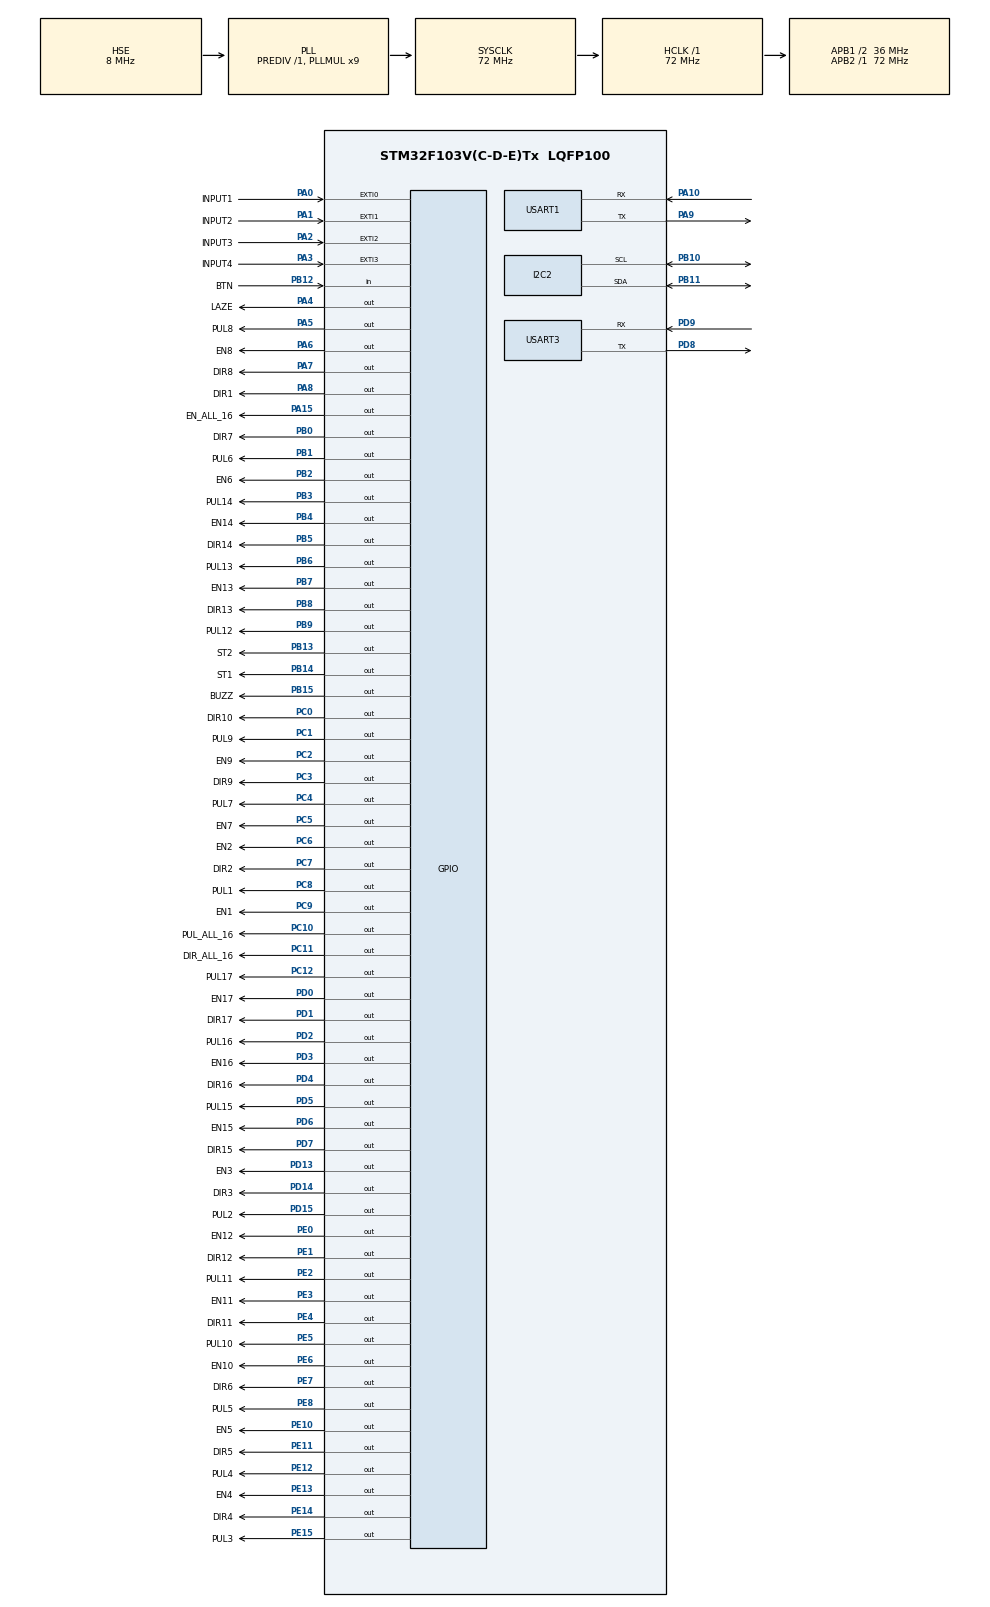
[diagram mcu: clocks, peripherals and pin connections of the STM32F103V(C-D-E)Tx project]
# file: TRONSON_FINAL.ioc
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I2C2.I2C_Mode=I2C_Standard
Mcu.Family=STM32F1
Mcu.Name=STM32F103V(C-D-E)Tx
Mcu.Package=LQFP100
NVIC.EXTI0_IRQn=true\:15\:0\:true\:false\:true\:true\:true\:true
NVIC.EXTI1_IRQn=true\:15\:0\:true\:false\:true\:true\:true\:true
NVIC.EXTI2_IRQn=true\:15\:0\:true\:false\:true\:true\:true\:true
NVIC.EXTI3_IRQn=true\:15\:0\:true\:false\:true\:true\:true\:true
NVIC.PriorityGroup=NVIC_PRIORITYGROUP_4
NVIC.TIM2_IRQn=true\:0\:0\:false\:false\:true\:true\:true\:true
NVIC.TIM3_IRQn=true\:2\:0\:true\:false\:true\:true\:true\:true
NVIC.TIM4_IRQn=true\:0\:0\:false\:false\:true\:true\:true\:true
NVIC.TIM5_IRQn=true\:0\:0\:false\:false\:true\:true\:true\:true
NVIC.TIM6_IRQn=true\:0\:0\:false\:false\:true\:true\:true\:true
NVIC.USART1_IRQn=true\:0\:0\:false\:false\:true\:true\:true\:true
NVIC.USART3_IRQn=true\:0\:0\:false\:false\:true\:true\:true\:true
OSC_IN.Mode=HSE-External-Oscillator
OSC_IN.Signal=RCC_OSC_IN
OSC_OUT.Mode=HSE-External-Oscillator
OSC_OUT.Signal=RCC_OSC_OUT
PA0-WKUP.GPIO_Label=INPUT1
PA0-WKUP.GPIO_ModeDefaultEXTI=GPIO_MODE_IT_RISING_FALLING
PA0-WKUP.GPIO_PuPd=GPIO_PULLUP
PA0-WKUP.Signal=GPXTI0
PA1.GPIO_Label=INPUT2
PA1.GPIO_ModeDefaultEXTI=GPIO_MODE_IT_RISING_FALLING
PA1.GPIO_PuPd=GPIO_PULLUP
PA1.Signal=GPXTI1
PA10.Mode=Asynchronous
PA10.Signal=USART1_RX
PA13.Signal=SYS_JTMS-SWDIO
PA14.Signal=SYS_JTCK-SWCLK
PA15.GPIO_Label=EN_ALL_16
PA15.GPIO_ModeDefaultOutputPP=GPIO_MODE_OUTPUT_PP
PA15.GPIO_PuPd=GPIO_NOPULL
PA15.GPIO_Speed=GPIO_SPEED_FREQ_LOW
PA15.PinState=GPIO_PIN_RESET
PA15.Signal=GPIO_Output
PA2.GPIO_Label=INPUT3
PA2.GPIO_ModeDefaultEXTI=GPIO_MODE_IT_RISING_FALLING
PA2.GPIO_PuPd=GPIO_PULLUP
PA2.Signal=GPXTI2
PA3.GPIO_Label=INPUT4
PA3.GPIO_ModeDefaultEXTI=GPIO_MODE_IT_RISING_FALLING
PA3.GPIO_PuPd=GPIO_PULLUP
PA3.Signal=GPXTI3
PA4.GPIO_Label=LAZE
PA4.Signal=GPIO_Output
PA5.GPIO_Label=PUL8
PA5.Signal=GPIO_Output
PA6.GPIO_Label=EN8
PA6.Signal=GPIO_Output
PA7.GPIO_Label=DIR8
PA7.Signal=GPIO_Output
PA8.GPIO_Label=DIR1
PA8.Signal=GPIO_Output
PA9.Mode=Asynchronous
PA9.Signal=USART1_TX
PB0.GPIO_Label=DIR7
PB0.Signal=GPIO_Output
PB1.GPIO_Label=PUL6
PB1.Signal=GPIO_Output
PB10.Mode=I2C
PB10.Signal=I2C2_SCL
PB11.Mode=I2C
PB11.Signal=I2C2_SDA
PB12.GPIO_Label=BTN
PB12.Signal=GPIO_Input
PB13.GPIO_Label=ST2
PB13.Signal=GPIO_Output
PB14.GPIO_Label=ST1
PB14.Signal=GPIO_Output
PB15.GPIO_Label=BUZZ
PB15.Signal=GPIO_Output
PB2.GPIO_Label=EN6
PB2.Signal=GPIO_Output
PB3.GPIO_Label=PUL14
PB3.Signal=GPIO_Output
PB4.GPIO_Label=EN14
PB4.Signal=GPIO_Output
PB5.GPIO_Label=DIR14
PB5.Signal=GPIO_Output
PB6.GPIO_Label=PUL13
PB6.Signal=GPIO_Output
PB7.GPIO_Label=EN13
PB7.Signal=GPIO_Output
PB8.GPIO_Label=DIR13
PB8.Signal=GPIO_Output
PB9.GPIO_Label=PUL12
PB9.Signal=GPIO_Output
PC0.GPIO_Label=DIR10
PC0.Signal=GPIO_Output
PC1.GPIO_Label=PUL9
PC1.Signal=GPIO_Output
PC10.GPIO_Label=PUL_ALL_16
PC10.Signal=GPIO_Output
PC11.GPIO_Label=DIR_ALL_16
PC11.Signal=GPIO_Output
PC12.GPIO_Label=PUL17
PC12.Signal=GPIO_Output
PC14-OSC32_IN.Mode=LSE-External-Oscillator
PC14-OSC32_IN.Signal=RCC_OSC32_IN
PC15-OSC32_OUT.Mode=LSE-External-Oscillator
PC15-OSC32_OUT.Signal=RCC_OSC32_OUT
PC2.GPIO_Label=EN9
PC2.Signal=GPIO_Output
PC3.GPIO_Label=DIR9
PC3.Signal=GPIO_Output
PC4.GPIO_Label=PUL7
PC4.Signal=GPIO_Output
PC5.GPIO_Label=EN7
PC5.Signal=GPIO_Output
PC6.GPIO_Label=EN2
PC6.Signal=GPIO_Output
PC7.GPIO_Label=DIR2
PC7.Signal=GPIO_Output
PC8.GPIO_Label=PUL1
PC8.Signal=GPIO_Output
PC9.GPIO_Label=EN1
PC9.Signal=GPIO_Output
PD0.GPIO_Label=EN17
PD0.Signal=GPIO_Output
PD1.GPIO_Label=DIR17
PD1.Signal=GPIO_Output
PD12.Signal=S_TIM4_CH1
PD13.GPIO_Label=EN3
PD13.Signal=GPIO_Output
PD14.GPIO_Label=DIR3
PD14.Signal=GPIO_Output
PD15.GPIO_Label=PUL2
PD15.Signal=GPIO_Output
PD2.GPIO_Label=PUL16
PD2.Signal=GPIO_Output
PD3.GPIO_Label=EN16
PD3.Signal=GPIO_Output
PD4.GPIO_Label=DIR16
PD4.Signal=GPIO_Output
PD5.GPIO_Label=PUL15
PD5.Signal=GPIO_Output
PD6.GPIO_Label=EN15
PD6.Signal=GPIO_Output
PD7.GPIO_Label=DIR15
PD7.Signal=GPIO_Output
PD8.Mode=Asynchronous
PD8.Signal=USART3_TX
PD9.Mode=Asynchronous
PD9.Signal=USART3_RX
PE0.GPIO_Label=EN12
PE0.GPIO_PuPd=GPIO_PULLUP
PE0.Signal=GPIO_Output
PE1.GPIO_Label=DIR12
PE1.GPIO_PuPd=GPIO_PULLUP
PE1.Signal=GPIO_Output
PE10.GPIO_Label=EN5
PE10.Signal=GPIO_Output
PE11.GPIO_Label=DIR5
PE11.Signal=GPIO_Output
PE12.GPIO_Label=PUL4
PE12.Signal=GPIO_Output
PE13.GPIO_Label=EN4
PE13.Signal=GPIO_Output
PE14.GPIO_Label=DIR4
PE14.Signal=GPIO_Output
PE15.GPIO_Label=PUL3
PE15.Signal=GPIO_Output
PE2.GPIO_Label=PUL11
PE2.GPIO_PuPd=GPIO_PULLUP
PE2.Signal=GPIO_Output
PE3.GPIO_Label=EN11
PE3.GPIO_PuPd=GPIO_PULLUP
PE3.Signal=GPIO_Output
PE4.GPIO_Label=DIR11
PE4.GPIO_PuPd=GPIO_PULLUP
PE4.Signal=GPIO_Output
PE5.GPIO_Label=PUL10
PE5.GPIO_PuPd=GPIO_PULLUP
PE5.Signal=GPIO_Output
PE6.GPIO_Label=EN10
PE6.GPIO_PuPd=GPIO_PULLUP
PE6.Signal=GPIO_Output
PE7.GPIO_Label=DIR6
PE7.Signal=GPIO_Output
PE8.GPIO_Label=PUL5
PE8.Signal=GPIO_Output
PE9.Signal=S_TIM1_CH1
ProjectManager.HeapSize=0x200
ProjectManager.StackSize=0x400
ProjectManager.TargetToolchain=STM32CubeIDE
RCC.AHBFreq_Value=72000000
RCC.APB1CLKDivider=RCC_HCLK_DIV2
RCC.APB1Freq_Value=36000000
RCC.APB1TimFreq_Value=72000000
RCC.APB2Freq_Value=72000000
RCC.APB2TimFreq_Value=72000000
RCC.HCLKFreq_Value=72000000
RCC.PLLMUL=RCC_PLL_MUL9
RCC.PLLSourceVirtual=RCC_PLLSOURCE_HSE
RCC.RTCClockSelection=RCC_RTCCLKSOURCE_LSE
RCC.SYSCLKFreq_VALUE=72000000
RCC.SYSCLKSource=RCC_SYSCLKSOURCE_PLLCLK
RCC.USBFreq_Value=48000000
RCC.USBPrescaler=RCC_USBCLKSOURCE_PLL_DIV1_5
SH.S_TIM1_CH1.0=TIM1_CH1
SH.S_TIM4_CH1.0=TIM4_CH1
TIM2.Period=9999
TIM2.Prescaler=7199
TIM3.AutoReloadPreload=TIM_AUTORELOAD_PRELOAD_ENABLE
TIM3.Period=9
TIM3.Prescaler=71
TIM4.AutoReloadPreload=TIM_AUTORELOAD_PRELOAD_ENABLE
TIM4.Period=72*100-1
TIM4.Prescaler=1
TIM5.Period=72*400-1
TIM6.AutoReloadPreload=TIM_AUTORELOAD_PRELOAD_ENABLE
TIM6.Period=9999
TIM6.Prescaler=71
USART1.VirtualMode=VM_ASYNC
USART3.VirtualMode=VM_ASYNC
VP_RTC_VS_RTC_Activate.Mode=RTC_Enabled
VP_TIM2_VS_ClockSourceINT.Mode=Internal
VP_TIM3_VS_ClockSourceINT.Mode=Internal
VP_TIM4_VS_ClockSourceINT.Mode=Internal
VP_TIM5_VS_ClockSourceINT.Mode=Internal
VP_TIM6_VS_ClockSourceINT.Mode=Enable_Timer
board=custom

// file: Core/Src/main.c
/* USER CODE BEGIN Header */
/**
  ******************************************************************************
  * @file           : main.c
  * @brief          : Main program body
  ******************************************************************************
  * @attention
  *
  * Copyright (c) 2023 STMicroelectronics.
  * All rights reserved.
  *
  * This software is licensed under terms that can be found in the LICENSE file
  * in the root directory of this software component.
  * If no LICENSE file comes with this software, it is provided AS-IS.
  *
  * edit: 0703 2024
  * fix loi dung dong thoi 2 dong co.
  *
  ******************************************************************************
  */
/* USER CODE END Header */
#include "main.h"
#include "i2c.h"
#include "rtc.h"
#include "tim.h"
#include "usart.h"
#include "gpio.h"

/* USER CODE BEGIN Includes */
/* USER CODE BEGIN Includes */
//#include "usbd_cdc_if.h"
#include <stdio.h>
//#include "SEGGER_RTT.h"

#include "board_peripheral.h"
#include "appPcHandle.h"
#include "eeprom_24c32.h"
#include "myEepromUtility.h"
#include "driver_rtc.h"
/* USER CODE END Includes */

/* USER CODE BEGIN PM */
#ifdef __GNUC__
#define PUTCHAR_PROTOTYPE int __io_putchar(int ch)
#else
#define PUTCHAR_PROTOTYPE int fputc(int ch, FILE *f)
#endif

PUTCHAR_PROTOTYPE
{
	HAL_UART_Transmit(&huart3, (uint8_t *)&ch, 1, HAL_MAX_DELAY);
    return ch;
}
/* USER CODE END PM */

/* USER CODE BEGIN PV */
void HAL_UART_RxCpltCallback(UART_HandleTypeDef *huart)
{
    //app PC //
    if(huart->Instance==huart1.Instance)
    {
    	uartAppHandle(&myApp);
    }
    HAL_UART_Receive_IT(&huart1, &myApp.charRec,1); //app PC
}
/* USER CODE END PV */

void SystemClock_Config(void);
/* USER CODE BEGIN PFP */
void RemapPin_Init(void) {

	// remap PA15 to free is GPIO //
	RCC->APB2ENR |= RCC_APB2ENR_AFIOEN | RCC_APB2ENR_IOPAEN;
	AFIO->MAPR   |= AFIO_MAPR_SWJ_CFG_1;    // To Free PA15

	// disable jtag //
	__HAL_RCC_AFIO_CLK_ENABLE();
	__HAL_AFIO_REMAP_SWJ_NOJTAG();
}

/* USER CODE END PFP */

/* USER CODE BEGIN 0 */

static volatile uint32_t Tick = 0;
/* USER CODE END 0 */

int main(void)
{
  /* USER CODE BEGIN 1 */
  /* SCB->VTOR = (uint32_t)(0x08008000);
    __enable_irq();*/
  /* USER CODE END 1 */

  /* MCU Configuration--------------------------------------------------------*/

  /* Reset of all peripherals, Initializes the Flash interface and the Systick. */
  HAL_Init();

  /* Configure the system clock */
  SystemClock_Config();

  /* USER CODE BEGIN SysInit */
  RemapPin_Init();
  //SEGGER_RTT_ConfigUpBuffer(0, NULL, NULL, 0 , SEGGER_RTT_MODE_NO_BLOCK_SKIP);
  /* USER CODE END SysInit */

  /* Initialize all configured peripherals */
  MX_GPIO_Init();
  MX_I2C2_Init();
  MX_TIM4_Init();
  MX_USART3_UART_Init();
  MX_TIM2_Init();
  MX_TIM3_Init();
  MX_TIM5_Init();
  MX_TIM6_Init();
  MX_RTC_Init();
  MX_USART1_UART_Init();
  /* USER CODE BEGIN 2 */

  HAL_UART_Receive_IT(&huart1, &myApp.charRec, 1);          //app PC
  DISABLE_TIMER_ALARM;

  /* USER CODE END 2 */

  /* Infinite loop */
  /* USER CODE BEGIN WHILE */

	printf("-----------------------------------------------------\r\n");
	printf("1.Start Application 07/05/2024 by xuantn93@gmail.com \r\n");
	printf("2.CPU_FREQ = %d Hz \r\n",  HAL_RCC_GetSysClockFreq());
	printf("3.Update Release 20/03/2025 \r\n");

	HAL_GPIO_WritePin(DIR17_GPIO_Port, DIR17_Pin, 1);
	speaker_efect();
	pump_init();
	loadConfigInEeprom();

	while (1)
	{
      handleAppRequets();
    /* USER CODE END WHILE */

	}
}

void SystemClock_Config(void)
{
  RCC_OscInitTypeDef RCC_OscInitStruct = {0};
  RCC_ClkInitTypeDef RCC_ClkInitStruct = {0};
  RCC_PeriphCLKInitTypeDef PeriphClkInit = {0};

  /** Initializes the RCC Oscillators according to the specified parameters
  * in the RCC_OscInitTypeDef structure.
  */
  RCC_OscInitStruct.OscillatorType = RCC_OSCILLATORTYPE_HSE|RCC_OSCILLATORTYPE_LSE;
  RCC_OscInitStruct.HSEState = RCC_HSE_ON;
  RCC_OscInitStruct.HSEPredivValue = RCC_HSE_PREDIV_DIV1;
  RCC_OscInitStruct.LSEState = RCC_LSE_ON;
  RCC_OscInitStruct.HSIState = RCC_HSI_ON;
  RCC_OscInitStruct.PLL.PLLState = RCC_PLL_ON;
  RCC_OscInitStruct.PLL.PLLSource = RCC_PLLSOURCE_HSE;
  RCC_OscInitStruct.PLL.PLLMUL = RCC_PLL_MUL9;
  if (HAL_RCC_OscConfig(&RCC_OscInitStruct) != HAL_OK)
  {
    Error_Handler();
  }

  /** Initializes the CPU, AHB and APB buses clocks
  */
  RCC_ClkInitStruct.ClockType = RCC_CLOCKTYPE_HCLK|RCC_CLOCKTYPE_SYSCLK
                              |RCC_CLOCKTYPE_PCLK1|RCC_CLOCKTYPE_PCLK2;
  RCC_ClkInitStruct.SYSCLKSource = RCC_SYSCLKSOURCE_PLLCLK;
  RCC_ClkInitStruct.AHBCLKDivider = RCC_SYSCLK_DIV1;
  RCC_ClkInitStruct.APB1CLKDivider = RCC_HCLK_DIV2;
  RCC_ClkInitStruct.APB2CLKDivider = RCC_HCLK_DIV1;

  if (HAL_RCC_ClockConfig(&RCC_ClkInitStruct, FLASH_LATENCY_2) != HAL_OK)
  {
    Error_Handler();
  }
  PeriphClkInit.PeriphClockSelection = RCC_PERIPHCLK_RTC;
  PeriphClkInit.RTCClockSelection = RCC_RTCCLKSOURCE_LSE;
  if (HAL_RCCEx_PeriphCLKConfig(&PeriphClkInit) != HAL_OK)
  {
    Error_Handler();
  }
}

/* USER CODE BEGIN 4 */
void HAL_TIM_PeriodElapsedCallback(TIM_HandleTypeDef *htim)
{
   if (htim->Instance == htim3.Instance)
      {
//	   	   HAL_GPIO_TogglePin(GPIOC, GPIO_PIN_14);
      }
   if (htim->Instance==TIM6)
      {
      //do something else here
      }
}
/* USER CODE END 4 */

void Error_Handler(void)
{
  __disable_irq();
  while (1)
  {
  }
}
